# SA3_SS0_PKTDMA_0_PKTDMA_CFG_GCFG register map
Vendor: Texas Instruments
Peripheral module from a debugger description file (folder am62P).
Registers are 32-bit, read-write, reset 0x0 unless marked. A register's access mark holds for its fields unless they carry their own. Offsets are as the file gives them; lines under a group give offsets from that group; [hi:lo] are bit positions; {n}, {i} and the like mark numbered series; 'fields as' and 'values as' point back to an identical list; <NAME> marks a mode.

## SA3_SS0_PKTDMA_0_PKTDMA_CFG_GCFG
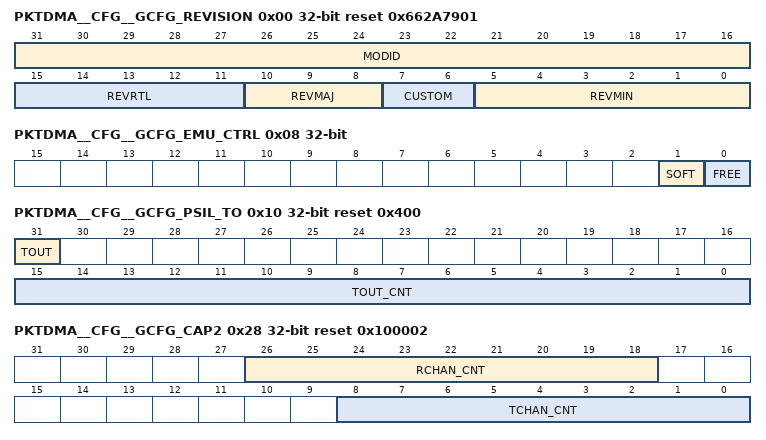
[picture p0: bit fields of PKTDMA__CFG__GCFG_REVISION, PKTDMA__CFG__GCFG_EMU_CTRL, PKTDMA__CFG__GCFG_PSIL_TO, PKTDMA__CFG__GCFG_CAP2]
0x00 PKTDMA__CFG__GCFG_REVISION ro reset 0x662A7901 — The Revision Register contains the major and minor revisions for the module.
  [31:16] MODID — Module ID field
  [15:11] REVRTL — RTL revision. Will vary depending on release.
  [10:8] REVMAJ — Major revision
  [7:6] CUSTOM
  [5:0] REVMIN — Minor revision
0x04 PKTDMA__CFG__GCFG_PERF_CTRL reset 0x40 — The performance control register contains fields which can be used to adjust the performance of the PKTDMA in the system.
  [15:0] TIMEOUT_CNT — This feature is not currently supported
0x08 PKTDMA__CFG__GCFG_EMU_CTRL — The emulation control register is used to control the behavior of the DMA when the emususp input is asserted.
  [1] SOFT, [0] FREE
0x10 PKTDMA__CFG__GCFG_PSIL_TO reset 0x400 — The PSI-L proxy timeout register controls the timeout watchdog and reports timeout occurrances on PSI-L configuration transactions issued by the built in PSI-L proxy.
  [31] TOUT — Timeout occurred. When set indicates that a timeout has occurred on a config access
  [15:0] TOUT_CNT — Timeout period. Specifies how many cycles to wait before closing up a conifiguration read or write transaction and asserting the tout bit
0x20 PKTDMA__CFG__GCFG_CAP0 access not given reset not defined — The Capabilities Register 0 specifies which standard features this PKTDMA instance supports.
0x24 PKTDMA__CFG__GCFG_CAP1 access not given reset not defined — The Capabilities Register 1 specifies which standard features this PKTDMA instance supports.
0x28 PKTDMA__CFG__GCFG_CAP2 ro reset 0x100002 — The Capabilities Register 2 specifies how many resources this PKTDMA instance supports.
  [26:18] RCHAN_CNT — Rx internal channel count
  [8:0] TCHAN_CNT — Tx internal channel count
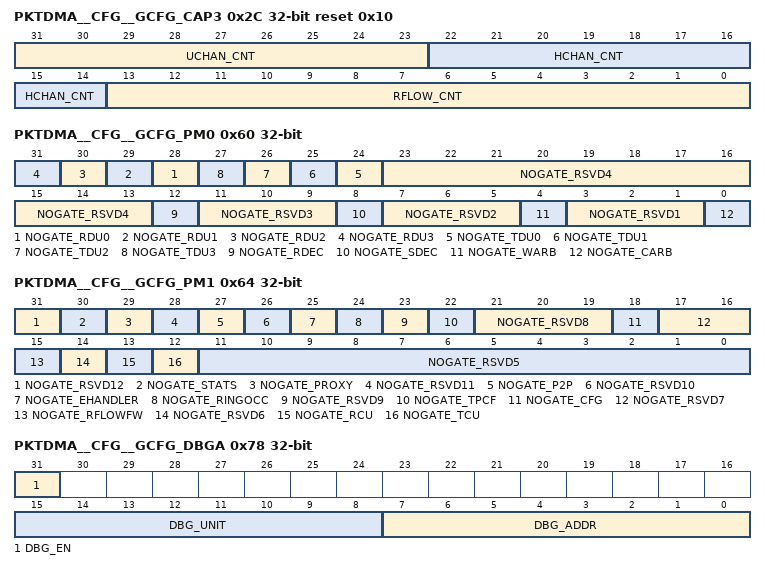
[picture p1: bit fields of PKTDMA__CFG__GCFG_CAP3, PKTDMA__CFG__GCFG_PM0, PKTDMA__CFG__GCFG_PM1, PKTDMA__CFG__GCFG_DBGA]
0x2C PKTDMA__CFG__GCFG_CAP3 ro reset 0x10 — The Capabilities Register 3 specifies how many resources this PKTDMA instance supports.
  [31:23] UCHAN_CNT — Tx ultra high capacity internal channel count
  [22:14] HCHAN_CNT — Tx high capacity internal channel count
  [13:0] RFLOW_CNT — Rx flow table entry count
0x30 PKTDMA__CFG__GCFG_CAP4 ro reset 0x10 — The Capabilities Register 4 specifies how many resources this PKTDMA instance supports.
  [13:0] TFLOW_CNT — Tx flow table entry count
0x60 PKTDMA__CFG__GCFG_PM0 — This register enables or inhibits automatic clock gating to individual sub-blocks
  [n+28] NOGATE_RDU{n} (n=0..3) — When set inhibits automatic gating of clock.
  [n+24] NOGATE_TDU{n} (n=0..3) — When set inhibits automatic gating of clock.
  [23:13] NOGATE_RSVD4 — Reserved PM signals.
  [12] NOGATE_RDEC — When set inhibits automatic gating of clock.
  [11:9] NOGATE_RSVD3 — Reserved PM signals.
  [8] NOGATE_SDEC — When set inhibits automatic gating of clock.
  [7:5] NOGATE_RSVD2 — Reserved PM signals.
  [4] NOGATE_WARB — When set inhibits automatic gating of clock.
  [3:1] NOGATE_RSVD1 — Reserved PM signals.
  [0] NOGATE_CARB — When set inhibits automatic gating of clock.
0x64 PKTDMA__CFG__GCFG_PM1 — This register enables or inhibits automatic clock gating to individual sub-blocks
  [31] NOGATE_RSVD12 — Reserved PM signals.
  [30] NOGATE_STATS — When set inhibits automatic gating of clock.
  [29] NOGATE_PROXY — When set inhibits automatic gating of clock.
  [28] NOGATE_RSVD11 — Reserved PM signals.
  [27] NOGATE_P2P — When set inhibits automatic gating of clock.
  [26] NOGATE_RSVD10 — Reserved PM signals.
  [25] NOGATE_EHANDLER — When set inhibits automatic gating of clock.
  [24] NOGATE_RINGOCC — When set inhibits automatic gating of clock.
  [23] NOGATE_RSVD9 — Reserved PM signals.
  [22] NOGATE_TPCF — When set inhibits automatic gating of clock.
  [21:19] NOGATE_RSVD8 — Reserved PM signals.
  [18] NOGATE_CFG — When set inhibits automatic gating of clock.
  [17:16] NOGATE_RSVD7 — Reserved PM signals.
  [15] NOGATE_RFLOWFW — When set inhibits automatic gating of clock.
  [14] NOGATE_RSVD6 — Reserved PM signals.
  [13] NOGATE_RCU — When set inhibits automatic gating of clock.
  [12] NOGATE_TCU — When set inhibits automatic gating of clock.
  [11:0] NOGATE_RSVD5 — Reserved PM signals.
0x78 PKTDMA__CFG__GCFG_DBGA — This register provides a writable address which allows debug information to be read from the Debug Data Register
  [31] DBG_EN — Debug enable
  [15:8] DBG_UNIT — Selects which unit to read debug information from
  [7:0] DBG_ADDR — Selects offset within unit to access seperate debug registers
0x7C PKTDMA__CFG__GCFG_DBGD ro — This register provides read only debug data
  [31:0] DBG_DATA — Provides debug information from various internal units. The value which is read back depends on which unit and register are selected in the Debug Address Register
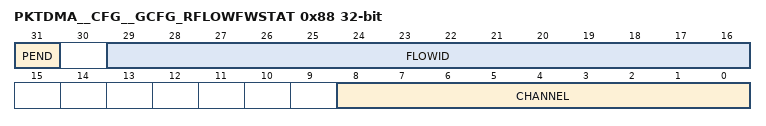
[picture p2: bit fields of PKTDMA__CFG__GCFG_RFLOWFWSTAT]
0x88 PKTDMA__CFG__GCFG_RFLOWFWSTAT — The Rx Flow FW Status Register 0 captures information about the thread/channel and received flow ID which failed a range check. Values in this register will remain persistent once an exception has been detected until the pend bit is written back to 0
  [31] PEND — This bit is set whenever the Flow ID firewall detects a Flow ID is out of range for an incoming packet. Once this bit is set, the remaining fields in this register will not be modified. SW is required to write this bit to 0 to allow another exception to be captured.
  [29:16] FLOWID — This is the flow ID that was received on the trapped packet
  [8:0] CHANNEL — This is the channel number on which the trapped packet was received
